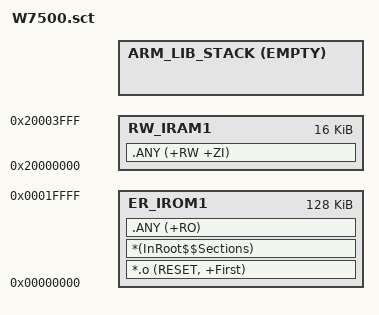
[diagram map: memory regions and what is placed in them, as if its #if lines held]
#! armcc -E
#include "mbed_config.h"
; *************************************************************
; *** Scatter-Loading Description File generated by uVision ***
; *************************************************************

#if (defined(__stack_size__))
  #define Stack_Size                   __stack_size__
#else
  #if (defined(MBED_CONF_RTOS_PRESENT))
    #define Stack_Size                   0x0400
  #else
    #define Stack_Size                   0x1000
  #endif
#endif

LR_IROM1 0x00000000 0x00020000  {    ; load region size_region
  ER_IROM1 0x00000000 0x00020000  {  ; load address = execution address
   *.o (RESET, +First)
   *(InRoot$$Sections)
   .ANY (+RO)
  }
  RW_IRAM1 0x20000000 0x00004000  {  ; RW data
   .ANY (+RW +ZI)
  }
  
  ARM_LIB_STACK 0x20000000+0x00004000 EMPTY -Stack_Size { ; Stack region growing down
  }
}

